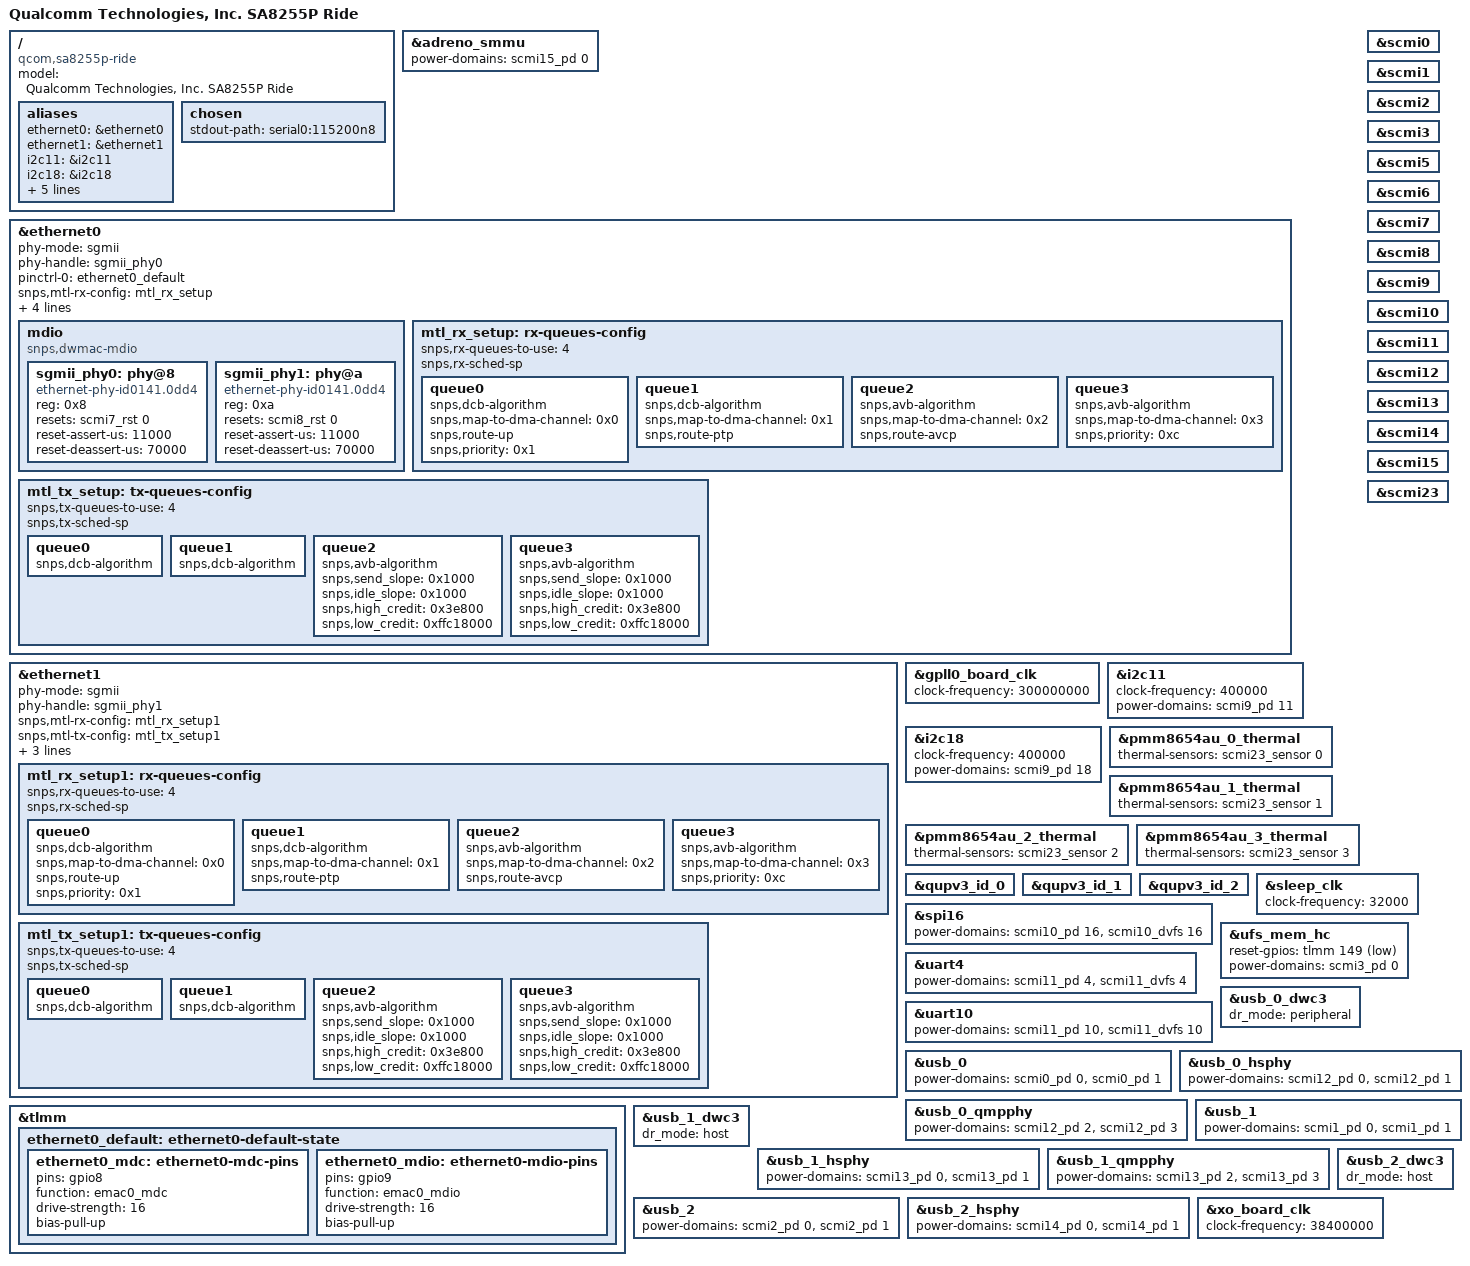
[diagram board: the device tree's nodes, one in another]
// SPDX-License-Identifier: BSD-3-Clause
/*
 * Copyright (c) 2024 Qualcomm Innovation Center, Inc. All rights reserved.
 */

/dts-v1/;

#include <dt-bindings/gpio/gpio.h>

#include "sa8255p.dtsi"
#include "sa8255p-pmics.dtsi"
#include "sa8255p-scmi.dtsi"

/ {
	model = "Qualcomm Technologies, Inc. SA8255P Ride";
	compatible = "qcom,sa8255p-ride","qcom,sa8255p";

	aliases {
		ethernet0 = &ethernet0;
		ethernet1 = &ethernet1;
		i2c11 = &i2c11;
		i2c18 = &i2c18;
		serial0 = &uart10;
		serial1 = &uart4;
		spi16 = &spi16;
		ufshc1 = &ufs_mem_hc;
		scmichannels = &scmichannels;
	};

	chosen {
		stdout-path = "serial0:115200n8";
	};
};

&adreno_smmu {
	power-domains = <&scmi15_pd 0>;

	status = "okay";
};

&ethernet0 {
	phy-mode = "sgmii";
	phy-handle = <&sgmii_phy0>;

	pinctrl-0 = <&ethernet0_default>;
	pinctrl-names = "default";

	snps,mtl-rx-config = <&mtl_rx_setup>;
	snps,mtl-tx-config = <&mtl_tx_setup>;
	snps,ps-speed = <1000>;

	power-domains = <&scmi7_pd 0>, <&scmi7_pd 1>,<&scmi7_dvfs 0>;
	power-domain-names = "power_core", "power_mdio","perf_serdes";

	status = "okay";

	mdio {
		compatible = "snps,dwmac-mdio";
		#address-cells = <1>;
		#size-cells = <0>;

		sgmii_phy0: phy@8 {
			compatible = "ethernet-phy-id0141.0dd4";
			reg = <0x8>;
			device_type = "ethernet-phy";
			resets = <&scmi7_rst 0>;
			reset-names = "phy";
			reset-assert-us = <11000>;
			reset-deassert-us = <70000>;
		};

		sgmii_phy1: phy@a {
			compatible = "ethernet-phy-id0141.0dd4";
			reg = <0xa>;
			device_type = "ethernet-phy";
			resets = <&scmi8_rst 0>;
			reset-names = "phy";
			reset-assert-us = <11000>;
			reset-deassert-us = <70000>;
		};
	};

	mtl_rx_setup: rx-queues-config {
		snps,rx-queues-to-use = <4>;
		snps,rx-sched-sp;

		queue0 {
			snps,dcb-algorithm;
			snps,map-to-dma-channel = <0x0>;
			snps,route-up;
			snps,priority = <0x1>;
		};

		queue1 {
			snps,dcb-algorithm;
			snps,map-to-dma-channel = <0x1>;
			snps,route-ptp;
		};

		queue2 {
			snps,avb-algorithm;
			snps,map-to-dma-channel = <0x2>;
			snps,route-avcp;
		};

		queue3 {
			snps,avb-algorithm;
			snps,map-to-dma-channel = <0x3>;
			snps,priority = <0xc>;
		};
	};

	mtl_tx_setup: tx-queues-config {
		snps,tx-queues-to-use = <4>;
		snps,tx-sched-sp;

		queue0 {
			snps,dcb-algorithm;
		};

		queue1 {
			snps,dcb-algorithm;
		};

		queue2 {
			snps,avb-algorithm;
			snps,send_slope = <0x1000>;
			snps,idle_slope = <0x1000>;
			snps,high_credit = <0x3e800>;
			snps,low_credit = <0xffc18000>;
		};

		queue3 {
			snps,avb-algorithm;
			snps,send_slope = <0x1000>;
			snps,idle_slope = <0x1000>;
			snps,high_credit = <0x3e800>;
			snps,low_credit = <0xffc18000>;
		};
	};
};

&ethernet1 {
	phy-mode = "sgmii";
	phy-handle = <&sgmii_phy1>;

	snps,mtl-rx-config = <&mtl_rx_setup1>;
	snps,mtl-tx-config = <&mtl_tx_setup1>;
	snps,ps-speed = <1000>;

	power-domains = <&scmi8_pd 0>, <&scmi8_pd 1>,<&scmi8_dvfs 0>;
	power-domain-names = "power_core", "power_mdio","perf_serdes";

	status = "okay";

	mtl_rx_setup1: rx-queues-config {
		snps,rx-queues-to-use = <4>;
		snps,rx-sched-sp;

		queue0 {
			snps,dcb-algorithm;
			snps,map-to-dma-channel = <0x0>;
			snps,route-up;
			snps,priority = <0x1>;
		};

		queue1 {
			snps,dcb-algorithm;
			snps,map-to-dma-channel = <0x1>;
			snps,route-ptp;
		};

		queue2 {
			snps,avb-algorithm;
			snps,map-to-dma-channel = <0x2>;
			snps,route-avcp;
		};

		queue3 {
			snps,avb-algorithm;
			snps,map-to-dma-channel = <0x3>;
			snps,priority = <0xc>;
		};
	};

	mtl_tx_setup1: tx-queues-config {
		snps,tx-queues-to-use = <4>;
		snps,tx-sched-sp;

		queue0 {
			snps,dcb-algorithm;
		};

		queue1 {
			snps,dcb-algorithm;
		};

		queue2 {
			snps,avb-algorithm;
			snps,send_slope = <0x1000>;
			snps,idle_slope = <0x1000>;
			snps,high_credit = <0x3e800>;
			snps,low_credit = <0xffc18000>;
		};

		queue3 {
			snps,avb-algorithm;
			snps,send_slope = <0x1000>;
			snps,idle_slope = <0x1000>;
			snps,high_credit = <0x3e800>;
			snps,low_credit = <0xffc18000>;
		};
	};
};

&gpll0_board_clk {
	clock-frequency = <300000000>;
};

&i2c11 {
	clock-frequency = <400000>;
	power-domains = <&scmi9_pd 11>;

	status = "okay";
};

&i2c18 {
	clock-frequency = <400000>;
	power-domains = <&scmi9_pd 18>;

	status = "okay";
};

&pmm8654au_0_thermal {
	thermal-sensors = <&scmi23_sensor 0>;
};

&pmm8654au_1_thermal {
	thermal-sensors = <&scmi23_sensor 1>;
};

&pmm8654au_2_thermal {
	thermal-sensors = <&scmi23_sensor 2>;
};

&pmm8654au_3_thermal {
	thermal-sensors = <&scmi23_sensor 3>;
};

&qupv3_id_0 {
	status = "okay";
};

&qupv3_id_1 {
	status = "okay";
};

&qupv3_id_2 {
	status = "okay";
};

&scmi0 {
	status = "okay";
};

&scmi1 {
	status = "okay";
};

&scmi2 {
	status = "okay";
};

&scmi3 {
	status = "okay";
};

&scmi5 {
	status = "okay";
};

&scmi6 {
	status = "okay";
};

&scmi7 {
	status = "okay";
};

&scmi8 {
	status = "okay";
};

&scmi9 {
	status = "okay";
};

&scmi10 {
	status = "okay";
};

&scmi11 {
	status = "okay";
};

&scmi12 {
	status = "okay";
};

&scmi13 {
	status = "okay";
};

&scmi14 {
	status = "okay";
};

&scmi15 {
	status = "okay";
};

&scmi23 {
	status = "okay";
};

&sleep_clk {
	clock-frequency = <32000>;
};

&spi16 {
	power-domains = <&scmi10_pd 16>, <&scmi10_dvfs 16>;
	power-domain-names = "power", "perf";

	status = "okay";
};

&tlmm {
	ethernet0_default: ethernet0-default-state {
		ethernet0_mdc: ethernet0-mdc-pins {
			pins = "gpio8";
			function = "emac0_mdc";
			drive-strength = <16>;
			bias-pull-up;
		};

		ethernet0_mdio: ethernet0-mdio-pins {
			pins = "gpio9";
			function = "emac0_mdio";
			drive-strength = <16>;
			bias-pull-up;
		};
	};
};

&uart4 {
	power-domains = <&scmi11_pd 4>, <&scmi11_dvfs 4>;
	power-domain-names = "power", "perf";

	status = "okay";
};

&uart10 {
	power-domains = <&scmi11_pd 10>, <&scmi11_dvfs 10>;
	power-domain-names = "power", "perf";

	status = "okay";
};

&ufs_mem_hc {
	reset-gpios = <&tlmm 149 GPIO_ACTIVE_LOW>;
	power-domains = <&scmi3_pd 0>;

	status = "okay";
};

&usb_0 {
	power-domains = <&scmi0_pd 0>, <&scmi0_pd 1>;
	power-domain-names = "usb_transfer", "usb_core";

	status = "okay";
};

&usb_0_dwc3 {
	dr_mode = "peripheral";
};

&usb_0_hsphy {
	power-domains = <&scmi12_pd 0>, <&scmi12_pd 1>;
	power-domain-names = "usb_transfer", "usb_core";

	status = "okay";
};

&usb_0_qmpphy {
	power-domains = <&scmi12_pd 2>, <&scmi12_pd 3>;
	power-domain-names = "usb_transfer", "usb_core";

	status = "okay";
};

&usb_1 {
	power-domains = <&scmi1_pd 0>, <&scmi1_pd 1>;
	power-domain-names = "usb_transfer", "usb_core";

	status = "okay";
};

&usb_1_dwc3 {
	dr_mode = "host";
};

&usb_1_hsphy {
	power-domains = <&scmi13_pd 0>, <&scmi13_pd 1>;
	power-domain-names = "usb_transfer", "usb_core";

	status = "okay";
};

&usb_1_qmpphy {
	power-domains = <&scmi13_pd 2>, <&scmi13_pd 3>;
	power-domain-names = "usb_transfer", "usb_core";

	status = "okay";
};

&usb_2 {
	power-domains = <&scmi2_pd 0>, <&scmi2_pd 1>;
	power-domain-names = "usb_transfer", "usb_core";

	status = "okay";
};

&usb_2_dwc3 {
	dr_mode = "host";
};

&usb_2_hsphy {
	power-domains = <&scmi14_pd 0>, <&scmi14_pd 1>;
	power-domain-names = "usb_transfer", "usb_core";

	status = "okay";
};

&xo_board_clk {
	clock-frequency = <38400000>;
};
